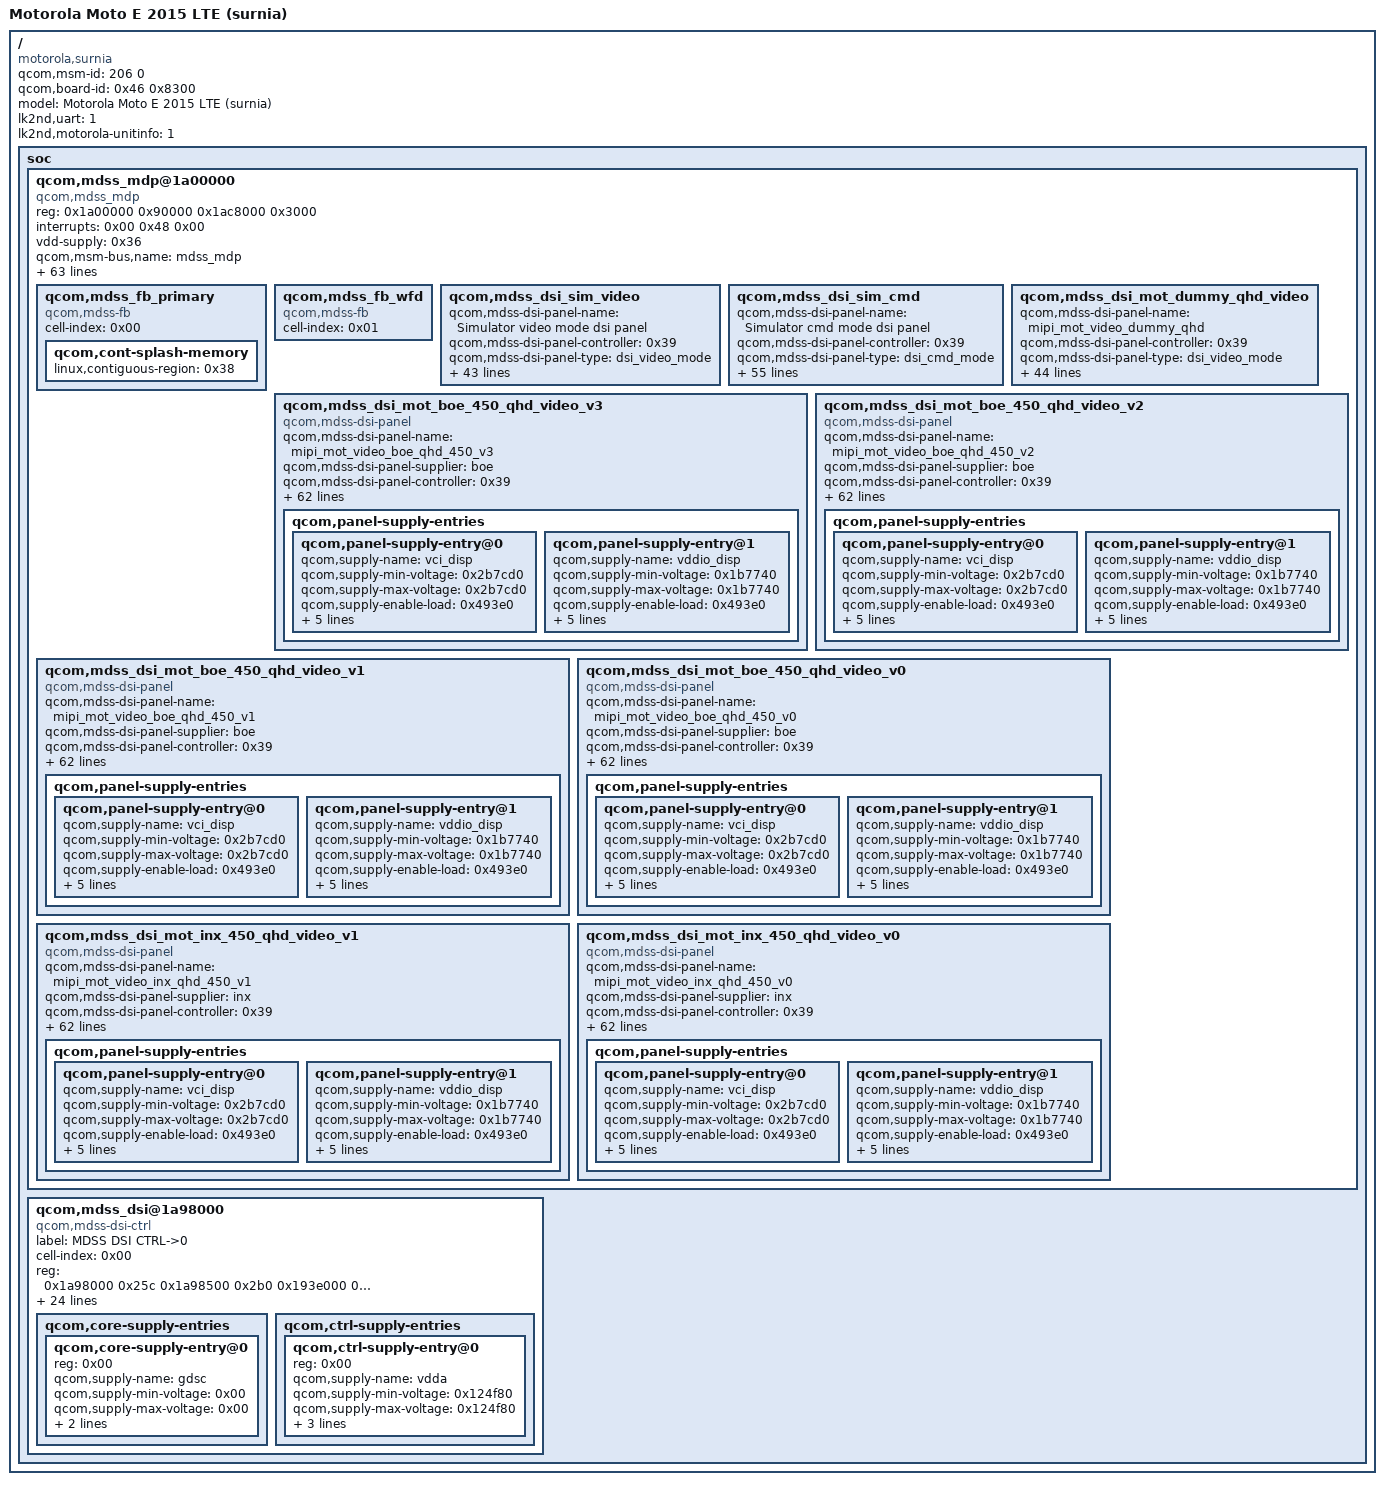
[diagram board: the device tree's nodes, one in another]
// SPDX-License-Identifier: GPL-2.0-only

/dts-v1/;

/include/ "msm8916.dtsi"
/include/ "motorola-carrier-channel-ids.dtsi"

/ {
	qcom,msm-id = <206 0>;
	qcom,board-id = <0x46 0x8300>;

	model = "Motorola Moto E 2015 LTE (surnia)";
	compatible = "motorola,surnia", "qcom,msm8916", "lk2nd,device";

	lk2nd,uart = <1>;
	lk2nd,motorola-unitinfo = <1>;

	soc {
		qcom,mdss_mdp@1a00000 {
			compatible = "qcom,mdss_mdp";
			reg = <0x1a00000 0x90000 0x1ac8000 0x3000>;
			reg-names = "mdp_phys\0vbif_phys";
			interrupts = <0x00 0x48 0x00>;
			vdd-supply = <0x36>;
			qcom,msm-bus,name = "mdss_mdp";
			qcom,msm-bus,num-cases = <0x03>;
			qcom,msm-bus,num-paths = <0x01>;
			qcom,msm-bus,vectors-KBps = <0x16 0x200 0x00 0x00 0x16 0x200 0x00 0x61a800 0x16 0x200 0x00 0x61a800>;
			qcom,mdss-ab-factor = <0x01 0x01>;
			qcom,mdss-ib-factor = <0x02 0x01>;
			qcom,mdss-clk-factor = <0x69 0x64>;
			qcom,max-bandwidth-low-kbps = <0x10c8e0>;
			qcom,max-bandwidth-high-kbps = <0x10c8e0>;
			qcom,mdss-vbif-qos-rt-setting = <0x02 0x02 0x02 0x02>;
			qcom,mdss-vbif-qos-nrt-setting = <0x01 0x01 0x01 0x01>;
			qcom,max-mixer-width = <0x800>;
			qcom,mdss-mdp-reg-offset = <0x1000>;
			qcom,max-clk-rate = <0x1312d000>;
			qcom,mdss-pipe-vig-off = <0x5000>;
			qcom,mdss-pipe-rgb-off = <0x15000 0x17000>;
			qcom,mdss-pipe-dma-off = <0x25000>;
			qcom,mdss-pipe-vig-fetch-id = <0x01>;
			qcom,mdss-pipe-rgb-fetch-id = <0x07 0x08>;
			qcom,mdss-pipe-dma-fetch-id = <0x04>;
			qcom,mdss-pipe-vig-xin-id = <0x00>;
			qcom,mdss-pipe-rgb-xin-id = <0x01 0x05>;
			qcom,mdss-pipe-dma-xin-id = <0x02>;
			qcom,mdss-pipe-vig-clk-ctrl-offsets = <0x2ac 0x00 0x00>;
			qcom,mdss-pipe-rgb-clk-ctrl-offsets = <0x2ac 0x04 0x08 0x2b4 0x04 0x08>;
			qcom,mdss-pipe-dma-clk-ctrl-offsets = <0x2ac 0x08 0x0c>;
			qcom,mdss-smp-data = <0x08 0x2000>;
			qcom,mdss-ctl-off = <0x2000 0x2200 0x2400>;
			qcom,mdss-mixer-intf-off = <0x45000>;
			qcom,mdss-mixer-wb-off = <0x48000>;
			qcom,mdss-dspp-off = <0x55000>;
			qcom,mdss-pingpong-off = <0x71000>;
			qcom,mdss-wb-off = <0x65000 0x65800 0x66000>;
			qcom,mdss-intf-off = <0x00 0x6b800>;
			qcom,mdss-rot-block-size = <0x40>;
			qcom,mdss-wfd-mode = "dedicated";
			qcom,mdss-has-non-scalar-rgb;
			qcom,mdss-has-decimation;
			qcom,mdss-traffic-shaper-enabled;
			qcom,mdss-no-hist-vote;
			vdd-cx-supply = <0x37>;
			clocks = <0x22 0xbfb92ed3 0x22 0x668f51de 0x22 0x6dc1f8f1 0x22 0x22f3521f 0x22 0x32a09f1f>;
			clock-names = "iface_clk\0bus_clk\0core_clk_src\0core_clk\0vsync_clk";
			qcom,mdp-settings = <0x11e4 0x00 0x65048 0x08 0x65848 0x08 0x66048 0x08>;
			qcom,mdss-prefill-outstanding-buffer-bytes = <0x400>;
			qcom,mdss-prefill-y-buffer-bytes = <0x00>;
			qcom,mdss-prefill-scaler-buffer-lines-bilinear = <0x02>;
			qcom,mdss-prefill-scaler-buffer-lines-caf = <0x04>;
			qcom,mdss-prefill-post-scaler-buffer-pixels = <0x00>;
			qcom,mdss-prefill-pingpong-buffer-pixels = <0x1000>;
			qcom,mdss-prefill-fbc-lines = <0x00>;
			qcom,mdss-pref-prim-intf = "dsi";
			linux,phandle = <0x3b>;
			phandle = <0x3b>;

			qcom,mdss_fb_primary {
				cell-index = <0x00>;
				compatible = "qcom,mdss-fb";
				linux,phandle = <0x3a>;
				phandle = <0x3a>;

				qcom,cont-splash-memory {
					linux,contiguous-region = <0x38>;
				};
			};

			qcom,mdss_fb_wfd {
				cell-index = <0x01>;
				compatible = "qcom,mdss-fb";
				linux,phandle = <0x43>;
				phandle = <0x43>;
			};

			qcom,mdss_dsi_sim_video {
				qcom,mdss-dsi-panel-name = "Simulator video mode dsi panel";
				qcom,mdss-dsi-panel-controller = <0x39>;
				qcom,mdss-dsi-panel-type = "dsi_video_mode";
				qcom,mdss-dsi-panel-destination = "display_1";
				qcom,mdss-dsi-panel-framerate = <0x3c>;
				qcom,mdss-dsi-virtual-channel-id = <0x00>;
				qcom,mdss-dsi-stream = <0x00>;
				qcom,mdss-dsi-panel-width = <0x280>;
				qcom,mdss-dsi-panel-height = <0x1e0>;
				qcom,mdss-dsi-h-front-porch = <0x06>;
				qcom,mdss-dsi-h-back-porch = <0x06>;
				qcom,mdss-dsi-h-pulse-width = <0x02>;
				qcom,mdss-dsi-h-sync-skew = <0x00>;
				qcom,mdss-dsi-v-back-porch = <0x06>;
				qcom,mdss-dsi-v-front-porch = <0x06>;
				qcom,mdss-dsi-v-pulse-width = <0x02>;
				qcom,mdss-dsi-h-left-border = <0x00>;
				qcom,mdss-dsi-h-right-border = <0x00>;
				qcom,mdss-dsi-v-top-border = <0x00>;
				qcom,mdss-dsi-v-bottom-border = <0x00>;
				qcom,mdss-dsi-bpp = <0x18>;
				qcom,mdss-dsi-underflow-color = <0xff>;
				qcom,mdss-dsi-border-color = <0x00>;
				qcom,mdss-dsi-on-command = [32 01 00 00 00 00 02 00 00];
				qcom,mdss-dsi-off-command = [22 01 00 00 00 00 02 00 00];
				qcom,mdss-dsi-on-command-state = "dsi_lp_mode";
				qcom,mdss-dsi-off-command-state = "dsi_lp_mode";
				qcom,mdss-dsi-h-sync-pulse = <0x00>;
				qcom,mdss-dsi-traffic-mode = "non_burst_sync_event";
				qcom,mdss-dsi-bllp-eof-power-mode;
				qcom,mdss-dsi-bllp-power-mode;
				qcom,mdss-dsi-lane-0-state;
				qcom,mdss-dsi-lane-1-state;
				qcom,mdss-dsi-lane-2-state;
				qcom,mdss-dsi-lane-3-state;
				qcom,mdss-dsi-panel-timings = <0x00 0x00 0x00>;
				qcom,mdss-dsi-t-clk-post = <0x04>;
				qcom,mdss-dsi-t-clk-pre = <0x1b>;
				qcom,mdss-dsi-dma-trigger = "trigger_sw";
				qcom,mdss-dsi-mdp-trigger = "none";
				qcom,mdss-dsi-reset-sequence = <0x01 0x00 0x00 0x00 0x01 0x00>;
				qcom,panel-ack-disabled;
			};

			qcom,mdss_dsi_sim_cmd {
				qcom,mdss-dsi-panel-name = "Simulator cmd mode dsi panel";
				qcom,mdss-dsi-panel-controller = <0x39>;
				qcom,mdss-dsi-panel-type = "dsi_cmd_mode";
				qcom,mdss-dsi-panel-destination = "display_1";
				qcom,mdss-dsi-panel-framerate = <0x3c>;
				qcom,mdss-dsi-virtual-channel-id = <0x00>;
				qcom,mdss-dsi-stream = <0x00>;
				qcom,mdss-dsi-panel-width = <0x438>;
				qcom,mdss-dsi-panel-height = <0x780>;
				qcom,mdss-dsi-h-front-porch = <0x60>;
				qcom,mdss-dsi-h-back-porch = <0x40>;
				qcom,mdss-dsi-h-pulse-width = <0x10>;
				qcom,mdss-dsi-h-sync-skew = <0x00>;
				qcom,mdss-dsi-v-back-porch = <0x10>;
				qcom,mdss-dsi-v-front-porch = <0x04>;
				qcom,mdss-dsi-v-pulse-width = <0x01>;
				qcom,mdss-dsi-h-left-border = <0x00>;
				qcom,mdss-dsi-h-right-border = <0x00>;
				qcom,mdss-dsi-v-top-border = <0x00>;
				qcom,mdss-dsi-v-bottom-border = <0x00>;
				qcom,mdss-dsi-bpp = <0x18>;
				qcom,mdss-dsi-color-order = "rgb_swap_rgb";
				qcom,mdss-dsi-underflow-color = <0xff>;
				qcom,mdss-dsi-border-color = <0x00>;
				qcom,mdss-dsi-h-sync-pulse = <0x00>;
				qcom,mdss-dsi-traffic-mode = "non_burst_sync_event";
				qcom,mdss-dsi-lane-map = "lane_map_0123";
				qcom,mdss-dsi-bllp-eof-power-mode;
				qcom,mdss-dsi-bllp-power-mode;
				qcom,mdss-dsi-lane-0-state;
				qcom,mdss-dsi-lane-1-state;
				qcom,mdss-dsi-lane-2-state;
				qcom,mdss-dsi-lane-3-state;
				qcom,mdss-dsi-hor-line-idle = <0x00 0x28 0x100 0x28 0x78 0x80 0x78 0xf0 0x40>;
				qcom,mdss-dsi-panel-timings = <0xcd322200 0x60642634 0x29030400>;
				qcom,mdss-dsi-reset-sequence = <0x01 0x0a 0x00 0x0a 0x01 0x0a>;
				qcom,mdss-dsi-t-clk-post = <0x03>;
				qcom,mdss-dsi-t-clk-pre = <0x27>;
				qcom,mdss-dsi-bl-max-level = <0xfff>;
				qcom,mdss-dsi-dma-trigger = "trigger_sw";
				qcom,mdss-dsi-mdp-trigger = "none";
				qcom,mdss-dsi-te-pin-select = <0x01>;
				qcom,mdss-dsi-wr-mem-start = <0x2c>;
				qcom,mdss-dsi-wr-mem-continue = <0x3c>;
				qcom,mdss-dsi-te-dcs-command = <0x01>;
				qcom,mdss-dsi-te-check-enable;
				qcom,mdss-dsi-te-using-te-pin;
				qcom,mdss-dsi-on-command = <0x29010000 0x2b0 0x3050100 0xa0001 0x150100 0xa0002 0x3a773901 0xa00 0x52a0000 0x4ff3901 0xa00 0x52b0000 0x59f1501 0xa00 0x2350039 0x100000a 0x34400 0x150100 0xa0002 0x51ff1501 0xa00 0x2532415 0x100000a 0x25500 0x5010000 0x78000111 0x5010000 0x10000129>;
				qcom,mdss-dsi-on-command-state = "dsi_lp_mode";
				qcom,mdss-dsi-off-command = [05 01 00 00 32 00 02 28 00 05 01 00 00 78 00 02 10 00];
				qcom,mdss-dsi-off-command-state = "dsi_hs_mode";
				qcom,panel-ack-disabled;
			};

			qcom,mdss_dsi_mot_dummy_qhd_video {
				qcom,mdss-dsi-panel-name = "mipi_mot_video_dummy_qhd";
				qcom,mdss-dsi-panel-controller = <0x39>;
				qcom,mdss-dsi-panel-type = "dsi_video_mode";
				qcom,mdss-dsi-panel-destination = "display_1";
				qcom,mdss-dsi-panel-framerate = <0x3c>;
				qcom,mdss-dsi-virtual-channel-id = <0x00>;
				qcom,mdss-dsi-stream = <0x00>;
				qcom,mdss-dsi-panel-width = <0x21c>;
				qcom,mdss-dsi-panel-height = <0x3c0>;
				qcom,mdss-pan-physical-width-dimension = <0x36>;
				qcom,mdss-pan-physical-height-dimension = <0x5f>;
				qcom,mdss-dsi-h-front-porch = <0x20>;
				qcom,mdss-dsi-h-back-porch = <0x04>;
				qcom,mdss-dsi-h-pulse-width = <0x20>;
				qcom,mdss-dsi-h-sync-skew = <0x00>;
				qcom,mdss-dsi-v-back-porch = <0x10>;
				qcom,mdss-dsi-v-front-porch = <0x0f>;
				qcom,mdss-dsi-v-pulse-width = <0x01>;
				qcom,mdss-dsi-h-left-border = <0x00>;
				qcom,mdss-dsi-h-right-border = <0x00>;
				qcom,mdss-dsi-v-top-border = <0x00>;
				qcom,mdss-dsi-v-bottom-border = <0x00>;
				qcom,mdss-dsi-bpp = <0x18>;
				qcom,mdss-dsi-underflow-color = <0xff>;
				qcom,mdss-dsi-border-color = <0x00>;
				qcom,mdss-dsi-on-command-state = "dsi_lp_mode";
				qcom,mdss-dsi-off-command-state = "dsi_lp_mode";
				qcom,mdss-dsi-h-sync-pulse = <0x00>;
				qcom,mdss-dsi-traffic-mode = "non_burst_sync_event";
				qcom,mdss-dsi-lane-map = "lane_map_3012";
				qcom,mdss-dsi-bllp-eof-power-mode;
				qcom,mdss-dsi-bllp-power-mode;
				qcom,mdss-dsi-lane-0-state;
				qcom,mdss-dsi-lane-1-state;
				qcom,mdss-dsi-tx-eot-append;
				qcom,mdss-dsi-panel-timings = <0x821c1200 0x4042161e 0x14030400>;
				qcom,mdss-dsi-t-clk-post = <0x04>;
				qcom,mdss-dsi-t-clk-pre = <0x1b>;
				qcom,mdss-dsi-bl-min-level = <0x01>;
				qcom,mdss-dsi-bl-max-level = <0xff>;
				qcom,mdss-dsi-dma-trigger = "trigger_sw";
				qcom,mdss-dsi-mdp-trigger = "none";
				qcom,mdss-dsi-bl-pmic-control-type = "bl_ctrl_dcs";
				qcom,mdss-dsi-reset-sequence = <0x01 0x00>;
			};

			qcom,mdss_dsi_mot_boe_450_qhd_video_v3 {
				compatible = "qcom,mdss-dsi-panel";
				qcom,mdss-dsi-panel-name = "mipi_mot_video_boe_qhd_450_v3";
				qcom,mdss-dsi-panel-supplier = "boe";
				qcom,mdss-dsi-panel-controller = <0x39>;
				qcom,mdss-dsi-panel-type = "dsi_video_mode";
				qcom,mdss-dsi-panel-destination = "display_1";
				qcom,mdss-dsi-panel-framerate = <0x3c>;
				qcom,mdss-dsi-virtual-channel-id = <0x00>;
				qcom,mdss-dsi-stream = <0x00>;
				qcom,mdss-dsi-panel-width = <0x21c>;
				qcom,mdss-dsi-panel-height = <0x3c0>;
				qcom,mdss-pan-physical-width-dimension = <0x37>;
				qcom,mdss-pan-physical-height-dimension = <0x63>;
				qcom,mdss-dsi-panel-clockrate = <0x00>;
				qcom,mdss-dsi-h-front-porch = <0x18>;
				qcom,mdss-dsi-h-back-porch = <0x28>;
				qcom,mdss-dsi-h-pulse-width = <0x04>;
				qcom,mdss-dsi-h-sync-skew = <0x00>;
				qcom,mdss-dsi-v-back-porch = <0x10>;
				qcom,mdss-dsi-v-front-porch = <0x10>;
				qcom,mdss-dsi-v-pulse-width = <0x02>;
				qcom,mdss-dsi-h-left-border = <0x00>;
				qcom,mdss-dsi-h-right-border = <0x00>;
				qcom,mdss-dsi-v-top-border = <0x00>;
				qcom,mdss-dsi-v-bottom-border = <0x00>;
				qcom,mdss-dsi-bpp = <0x18>;
				qcom,mdss-dsi-underflow-color = <0xff>;
				qcom,mdss-dsi-border-color = <0x00>;
				qcom,mdss-dsi-on-command = [15 01 00 00 00 00 02 53 2c 15 01 00 00 00 00 02 55 02 05 01 00 00 78 00 01 11 15 01 00 00 00 00 02 51 ff 05 01 00 00 28 00 01 29];
				qcom,mdss-dsi-off-command = <0x5010000 0xa000128 0x5010000 0x78000110>;
				qcom,mdss-dsi-on-command-state = "dsi_lp_mode";
				qcom,mdss-dsi-off-command-state = "dsi_lp_mode";
				qcom,mdss-dsi-h-sync-pulse = <0x00>;
				qcom,mdss-dsi-traffic-mode = "non_burst_sync_event";
				qcom,mdss-dsi-bllp-eof-power-mode;
				qcom,mdss-dsi-bllp-power-mode;
				qcom,mdss-dsi-lane-0-state;
				qcom,mdss-dsi-lane-1-state;
				qcom,mdss-dsi-panel-timings = <0x821c1200 0x4042161e 0x14030400>;
				qcom,mdss-dsi-t-clk-post = <0x04>;
				qcom,mdss-dsi-t-clk-pre = <0x1a>;
				qcom,mdss-dsi-bl-min-level = <0x01>;
				qcom,mdss-dsi-bl-max-level = <0xff>;
				qcom,mdss-dsi-bl-shutdown-delay = <0x28>;
				qcom,mdss-dsi-bl-on-defer-delay = <0x78>;
				qcom,mdss-dsi-dma-trigger = "trigger_sw";
				qcom,mdss-dsi-mdp-trigger = "none";
				qcom,mdss-dsi-bl-pmic-control-type = "bl_ctrl_wled";
				qcom,mdss-dsi-reset-sequence = <0x01 0x02 0x00 0x01 0x01 0x15>;
				qcom,mdss-dsi-lp11-init;
				qcom,mdss-dsi-tx-eot-append;
				qcom,esd-check-enabled;
				qcom,mdss-dsi-panel-status-check-mode = "reg_read";
				qcom,mdss-dsi-panel-status-command = <0x6010001 0x10a>;
				qcom,mdss-dsi-panel-status-command-state = "dsi_hs_mode";
				qcom,mdss-dsi-panel-status-value = <0x9c>;
				qcom,cont-splash-enabled;
				linux,phandle = <0x42>;
				phandle = <0x42>;

				qcom,panel-supply-entries {
					#address-cells = <0x01>;
					#size-cells = <0x00>;

					qcom,panel-supply-entry@0 {
						qcom,supply-name = "vci_disp";
						qcom,supply-min-voltage = <0x2b7cd0>;
						qcom,supply-max-voltage = <0x2b7cd0>;
						qcom,supply-enable-load = <0x493e0>;
						qcom,supply-disable-load = <0x64>;
						qcom,supply-pre-on-sleep = <0x00>;
						qcom,supply-post-on-sleep = <0x00>;
						qcom,supply-pre-off-sleep = <0x00>;
						qcom,supply-post-off-sleep = <0x00>;
					};

					qcom,panel-supply-entry@1 {
						qcom,supply-name = "vddio_disp";
						qcom,supply-min-voltage = <0x1b7740>;
						qcom,supply-max-voltage = <0x1b7740>;
						qcom,supply-enable-load = <0x493e0>;
						qcom,supply-disable-load = <0x64>;
						qcom,supply-pre-on-sleep = <0x00>;
						qcom,supply-post-on-sleep = <0x00>;
						qcom,supply-pre-off-sleep = <0x00>;
						qcom,supply-post-off-sleep = <0x00>;
					};
				};
			};

			qcom,mdss_dsi_mot_boe_450_qhd_video_v2 {
				compatible = "qcom,mdss-dsi-panel";
				qcom,mdss-dsi-panel-name = "mipi_mot_video_boe_qhd_450_v2";
				qcom,mdss-dsi-panel-supplier = "boe";
				qcom,mdss-dsi-panel-controller = <0x39>;
				qcom,mdss-dsi-panel-type = "dsi_video_mode";
				qcom,mdss-dsi-panel-destination = "display_1";
				qcom,mdss-dsi-panel-framerate = <0x3c>;
				qcom,mdss-dsi-virtual-channel-id = <0x00>;
				qcom,mdss-dsi-stream = <0x00>;
				qcom,mdss-dsi-panel-width = <0x21c>;
				qcom,mdss-dsi-panel-height = <0x3c0>;
				qcom,mdss-pan-physical-width-dimension = <0x37>;
				qcom,mdss-pan-physical-height-dimension = <0x63>;
				qcom,mdss-dsi-panel-clockrate = <0x00>;
				qcom,mdss-dsi-h-front-porch = <0x18>;
				qcom,mdss-dsi-h-back-porch = <0x28>;
				qcom,mdss-dsi-h-pulse-width = <0x04>;
				qcom,mdss-dsi-h-sync-skew = <0x00>;
				qcom,mdss-dsi-v-back-porch = <0x10>;
				qcom,mdss-dsi-v-front-porch = <0x10>;
				qcom,mdss-dsi-v-pulse-width = <0x02>;
				qcom,mdss-dsi-h-left-border = <0x00>;
				qcom,mdss-dsi-h-right-border = <0x00>;
				qcom,mdss-dsi-v-top-border = <0x00>;
				qcom,mdss-dsi-v-bottom-border = <0x00>;
				qcom,mdss-dsi-bpp = <0x18>;
				qcom,mdss-dsi-underflow-color = <0xff>;
				qcom,mdss-dsi-border-color = <0x00>;
				qcom,mdss-dsi-on-command = <0x29010000 0x6f0 0x55aa5208 0x290100 0x06 0xb0000c40 0x3c3c2901 0x00 0x3b16b06 0x13010000 0x2b6 0x9290100 0x03 0xb7030229 0x1000000 0x5b801 0x4040413 0x1000000 0x2ba01 0x29010000 0x3bb 0x63301301 0x00 0x2bc0029 0x1000000 0x4cc03 0x17502901 0x00 0xad40000 0x00 0x29 0x1000000 0x11d600 0x101 0x1010101 0x1010102 0x2020229 0x1000000 0xdd731 0x31313131 0x31313131 0x31313129 0x1000000 0xed831 0x31313131 0x31313131 0x31313131 0x29010000 0xbe3 0xf0e4ded7 0xd0cbc9c6 0xc3c02901 0x00 0x6f055aa 0x52080113 0x1000000 0x2b00a 0x13010000 0x2b6 0x33130100 0x02 0xb10a1301 0x00 0x2b72413 0x1000000 0x2b201 0x13010000 0x2b8 0x33130100 0x02 0xb30a1301 0x00 0x2b92313 0x1000000 0x2b40a 0x13010000 0x2ba 0x25150100 0x02 0x532c1501 0x00 0x2550205 0x1000078 0x11115 0x1000000 0x251ff 0x5010000 0x28000129>;
				qcom,mdss-dsi-off-command = <0x5010000 0xa000128 0x5010000 0x78000110>;
				qcom,mdss-dsi-on-command-state = "dsi_lp_mode";
				qcom,mdss-dsi-off-command-state = "dsi_lp_mode";
				qcom,mdss-dsi-h-sync-pulse = <0x00>;
				qcom,mdss-dsi-traffic-mode = "non_burst_sync_event";
				qcom,mdss-dsi-bllp-eof-power-mode;
				qcom,mdss-dsi-bllp-power-mode;
				qcom,mdss-dsi-lane-0-state;
				qcom,mdss-dsi-lane-1-state;
				qcom,mdss-dsi-panel-timings = <0x821c1200 0x4042161e 0x14030400>;
				qcom,mdss-dsi-t-clk-post = <0x04>;
				qcom,mdss-dsi-t-clk-pre = <0x1a>;
				qcom,mdss-dsi-bl-min-level = <0x01>;
				qcom,mdss-dsi-bl-max-level = <0xff>;
				qcom,mdss-dsi-bl-shutdown-delay = <0x28>;
				qcom,mdss-dsi-bl-on-defer-delay = <0x78>;
				qcom,mdss-dsi-dma-trigger = "trigger_sw";
				qcom,mdss-dsi-mdp-trigger = "none";
				qcom,mdss-dsi-bl-pmic-control-type = "bl_ctrl_wled";
				qcom,mdss-dsi-reset-sequence = <0x01 0x02 0x00 0x01 0x01 0x15>;
				qcom,mdss-dsi-lp11-init;
				qcom,mdss-dsi-tx-eot-append;
				qcom,esd-check-enabled;
				qcom,mdss-dsi-panel-status-check-mode = "reg_read";
				qcom,mdss-dsi-panel-status-command = <0x6010001 0x10a>;
				qcom,mdss-dsi-panel-status-command-state = "dsi_hs_mode";
				qcom,mdss-dsi-panel-status-value = <0x9c>;
				qcom,cont-splash-enabled;

				qcom,panel-supply-entries {
					#address-cells = <0x01>;
					#size-cells = <0x00>;

					qcom,panel-supply-entry@0 {
						qcom,supply-name = "vci_disp";
						qcom,supply-min-voltage = <0x2b7cd0>;
						qcom,supply-max-voltage = <0x2b7cd0>;
						qcom,supply-enable-load = <0x493e0>;
						qcom,supply-disable-load = <0x64>;
						qcom,supply-pre-on-sleep = <0x00>;
						qcom,supply-post-on-sleep = <0x00>;
						qcom,supply-pre-off-sleep = <0x00>;
						qcom,supply-post-off-sleep = <0x00>;
					};

					qcom,panel-supply-entry@1 {
						qcom,supply-name = "vddio_disp";
						qcom,supply-min-voltage = <0x1b7740>;
						qcom,supply-max-voltage = <0x1b7740>;
						qcom,supply-enable-load = <0x493e0>;
						qcom,supply-disable-load = <0x64>;
						qcom,supply-pre-on-sleep = <0x00>;
						qcom,supply-post-on-sleep = <0x00>;
						qcom,supply-pre-off-sleep = <0x00>;
						qcom,supply-post-off-sleep = <0x00>;
					};
				};
			};

			qcom,mdss_dsi_mot_boe_450_qhd_video_v1 {
				compatible = "qcom,mdss-dsi-panel";
				qcom,mdss-dsi-panel-name = "mipi_mot_video_boe_qhd_450_v1";
				qcom,mdss-dsi-panel-supplier = "boe";
				qcom,mdss-dsi-panel-controller = <0x39>;
				qcom,mdss-dsi-panel-type = "dsi_video_mode";
				qcom,mdss-dsi-panel-destination = "display_1";
				qcom,mdss-dsi-panel-framerate = <0x3c>;
				qcom,mdss-dsi-virtual-channel-id = <0x00>;
				qcom,mdss-dsi-stream = <0x00>;
				qcom,mdss-dsi-panel-width = <0x21c>;
				qcom,mdss-dsi-panel-height = <0x3c0>;
				qcom,mdss-pan-physical-width-dimension = <0x37>;
				qcom,mdss-pan-physical-height-dimension = <0x63>;
				qcom,mdss-dsi-panel-clockrate = <0x00>;
				qcom,mdss-dsi-h-front-porch = <0x18>;
				qcom,mdss-dsi-h-back-porch = <0x28>;
				qcom,mdss-dsi-h-pulse-width = <0x04>;
				qcom,mdss-dsi-h-sync-skew = <0x00>;
				qcom,mdss-dsi-v-back-porch = <0x10>;
				qcom,mdss-dsi-v-front-porch = <0x10>;
				qcom,mdss-dsi-v-pulse-width = <0x02>;
				qcom,mdss-dsi-h-left-border = <0x00>;
				qcom,mdss-dsi-h-right-border = <0x00>;
				qcom,mdss-dsi-v-top-border = <0x00>;
				qcom,mdss-dsi-v-bottom-border = <0x00>;
				qcom,mdss-dsi-bpp = <0x18>;
				qcom,mdss-dsi-underflow-color = <0xff>;
				qcom,mdss-dsi-border-color = <0x00>;
				qcom,mdss-dsi-on-command = [29 01 00 00 00 00 06 f0 55 aa 52 08 00 29 01 00 00 00 00 06 b0 00 0c 40 3c 3c 29 01 00 00 00 00 03 b1 fc 06 13 01 00 00 00 00 02 b6 09 29 01 00 00 00 00 03 b7 03 02 29 01 00 00 00 00 05 b8 01 02 02 02 13 01 00 00 00 00 02 ba 01 13 01 00 00 00 00 02 bc 00 29 01 00 00 00 00 04 cc 03 17 50 29 01 00 00 00 00 0a d4 00 00 00 00 00 00 00 00 00 29 01 00 00 00 00 11 d6 00 00 00 01 01 01 01 01 01 01 01 01 02 02 02 02 29 01 00 00 00 00 0d d7 31 31 31 31 31 31 31 31 31 31 31 31 29 01 00 00 00 00 0e d8 31 31 31 31 31 31 31 31 31 31 31 31 31 29 01 00 00 00 00 0b e3 f0 e4 de d7 d0 cb c9 c6 c3 c0 29 01 00 00 00 00 06 f0 55 aa 52 08 01 13 01 00 00 00 00 02 b0 0a 13 01 00 00 00 00 02 b6 43 13 01 00 00 00 00 02 b1 0a 13 01 00 00 00 00 02 b7 34 13 01 00 00 00 00 02 b2 00 13 01 00 00 00 00 02 b8 13 13 01 00 00 00 00 02 b3 0a 13 01 00 00 00 00 02 b9 23 13 01 00 00 00 00 02 b4 0a 13 01 00 00 00 00 02 ba 24 15 01 00 00 00 00 02 53 2c 15 01 00 00 00 00 02 55 02 05 01 00 00 78 00 01 11 15 01 00 00 00 00 02 51 ff 05 01 00 00 28 00 01 29];
				qcom,mdss-dsi-off-command = <0x5010000 0xa000128 0x5010000 0x78000110>;
				qcom,mdss-dsi-on-command-state = "dsi_lp_mode";
				qcom,mdss-dsi-off-command-state = "dsi_lp_mode";
				qcom,mdss-dsi-h-sync-pulse = <0x00>;
				qcom,mdss-dsi-traffic-mode = "non_burst_sync_event";
				qcom,mdss-dsi-bllp-eof-power-mode;
				qcom,mdss-dsi-bllp-power-mode;
				qcom,mdss-dsi-lane-0-state;
				qcom,mdss-dsi-lane-1-state;
				qcom,mdss-dsi-panel-timings = <0x821c1200 0x4042161e 0x14030400>;
				qcom,mdss-dsi-t-clk-post = <0x04>;
				qcom,mdss-dsi-t-clk-pre = <0x1a>;
				qcom,mdss-dsi-bl-min-level = <0x01>;
				qcom,mdss-dsi-bl-max-level = <0xff>;
				qcom,mdss-dsi-bl-shutdown-delay = <0x28>;
				qcom,mdss-dsi-bl-on-defer-delay = <0x78>;
				qcom,mdss-dsi-dma-trigger = "trigger_sw";
				qcom,mdss-dsi-mdp-trigger = "none";
				qcom,mdss-dsi-bl-pmic-control-type = "bl_ctrl_wled";
				qcom,mdss-dsi-reset-sequence = <0x01 0x02 0x00 0x01 0x01 0x15>;
				qcom,mdss-dsi-lp11-init;
				qcom,mdss-dsi-tx-eot-append;
				qcom,esd-check-enabled;
				qcom,mdss-dsi-panel-status-check-mode = "reg_read";
				qcom,mdss-dsi-panel-status-command = <0x6010001 0x10a>;
				qcom,mdss-dsi-panel-status-command-state = "dsi_hs_mode";
				qcom,mdss-dsi-panel-status-value = <0x9c>;
				qcom,cont-splash-enabled;

				qcom,panel-supply-entries {
					#address-cells = <0x01>;
					#size-cells = <0x00>;

					qcom,panel-supply-entry@0 {
						qcom,supply-name = "vci_disp";
						qcom,supply-min-voltage = <0x2b7cd0>;
						qcom,supply-max-voltage = <0x2b7cd0>;
						qcom,supply-enable-load = <0x493e0>;
						qcom,supply-disable-load = <0x64>;
						qcom,supply-pre-on-sleep = <0x00>;
						qcom,supply-post-on-sleep = <0x00>;
						qcom,supply-pre-off-sleep = <0x00>;
						qcom,supply-post-off-sleep = <0x00>;
					};

					qcom,panel-supply-entry@1 {
						qcom,supply-name = "vddio_disp";
						qcom,supply-min-voltage = <0x1b7740>;
						qcom,supply-max-voltage = <0x1b7740>;
						qcom,supply-enable-load = <0x493e0>;
						qcom,supply-disable-load = <0x64>;
						qcom,supply-pre-on-sleep = <0x00>;
						qcom,supply-post-on-sleep = <0x00>;
						qcom,supply-pre-off-sleep = <0x00>;
						qcom,supply-post-off-sleep = <0x00>;
					};
				};
			};

			qcom,mdss_dsi_mot_boe_450_qhd_video_v0 {
				compatible = "qcom,mdss-dsi-panel";
				qcom,mdss-dsi-panel-name = "mipi_mot_video_boe_qhd_450_v0";
				qcom,mdss-dsi-panel-supplier = "boe";
				qcom,mdss-dsi-panel-controller = <0x39>;
				qcom,mdss-dsi-panel-type = "dsi_video_mode";
				qcom,mdss-dsi-panel-destination = "display_1";
				qcom,mdss-dsi-panel-framerate = <0x3c>;
				qcom,mdss-dsi-virtual-channel-id = <0x00>;
				qcom,mdss-dsi-stream = <0x00>;
				qcom,mdss-dsi-panel-width = <0x21c>;
				qcom,mdss-dsi-panel-height = <0x3c0>;
				qcom,mdss-pan-physical-width-dimension = <0x37>;
				qcom,mdss-pan-physical-height-dimension = <0x63>;
				qcom,mdss-dsi-panel-clockrate = <0x00>;
				qcom,mdss-dsi-h-front-porch = <0x18>;
				qcom,mdss-dsi-h-back-porch = <0x28>;
				qcom,mdss-dsi-h-pulse-width = <0x04>;
				qcom,mdss-dsi-h-sync-skew = <0x00>;
				qcom,mdss-dsi-v-back-porch = <0x10>;
				qcom,mdss-dsi-v-front-porch = <0x10>;
				qcom,mdss-dsi-v-pulse-width = <0x02>;
				qcom,mdss-dsi-h-left-border = <0x00>;
				qcom,mdss-dsi-h-right-border = <0x00>;
				qcom,mdss-dsi-v-top-border = <0x00>;
				qcom,mdss-dsi-v-bottom-border = <0x00>;
				qcom,mdss-dsi-bpp = <0x18>;
				qcom,mdss-dsi-underflow-color = <0xff>;
				qcom,mdss-dsi-border-color = <0x00>;
				qcom,mdss-dsi-on-command = <0x29010000 0x6f0 0x55aa5208 0x290100 0x02 0xb6082901 0x00 0x3b70000 0x29010000 0x2bc 0x290100 0x04 0xcc030000 0x29010000 0x6f0 0x55aa5208 0x1290100 0x04 0xb00a0a0a 0x29010000 0x4b6 0x44444429 0x1000000 0x4b10a 0xa0a2901 0x00 0x4b72424 0x24290100 0x04 0xb2030303 0x29010000 0x4b8 0x33333329 0x1000000 0x4b30d 0xd0d2901 0x00 0x4b92424 0x24290100 0x04 0xb40a0a0a 0x29010000 0x4ba 0x24242429 0x1000000 0x4bc00 0x78002901 0x00 0x4bd0078 0x290100 0x02 0xbe4f2901 0x00 0x11d10095 0xa800b8 0xc900e2 0xf30102 0x12b2901 0x00 0x11d2015e 0x19501d1 0x2090234 0x2550268 0x29f2901 0x00 0x11d302d3 0x3020312 0x33f035e 0x384039b 0x3b92901 0x00 0x5d403f1 0x3ff2901 0x00 0x11d50043 0x580078 0x9000a2 0xc300de 0x10b2901 0x00 0x11d6012e 0x1650191 0x1d90214 0x2150248 0x27f2901 0x00 0x11d702a3 0x2d202f2 0x31f033e 0x364037b 0x3992901 0x00 0x5d803e1 0x3ff2901 0x00 0x11d90043 0x580078 0x9000a2 0xc300de 0x10b2901 0x00 0x11dd012e 0x1650191 0x1d90214 0x2150248 0x27f2901 0x00 0x11de02a3 0x2d202f2 0x31f033e 0x364037b 0x3992901 0x00 0x11e00095 0xa800b8 0xc900e2 0xf30102 0x12b2901 0x00 0x11e1015e 0x19501d1 0x2090234 0x2550268 0x29f2901 0x00 0x11e202d3 0x3020312 0x33f035e 0x384039b 0x3b92901 0x00 0x5e303f1 0x3ff2901 0x00 0x11e40043 0x580078 0x9000a2 0xc300de 0x10b2901 0x00 0x11e5012e 0x1650191 0x1d90214 0x2150248 0x27f2901 0x00 0x11e602a3 0x2d202f2 0x31f033e 0x364037b 0x3992901 0x00 0x5e703e1 0x3ff2901 0x00 0x11e80043 0x580078 0x9000a2 0xc300de 0x10b2901 0x00 0x11e9012e 0x1650191 0x1d90214 0x2150248 0x27f2901 0x00 0x11ea02a3 0x2d202f2 0x31f033e 0x364037b 0x3992901 0x00 0x5eb03e1 0x3ff0501 0x7800 0x1111501 0x00 0x2532c15 0x1000000 0x251ff 0x5010000 0x28000129>;
				qcom,mdss-dsi-off-command = <0x5010000 0xa000128 0x5010000 0x78000110>;
				qcom,mdss-dsi-on-command-state = "dsi_lp_mode";
				qcom,mdss-dsi-off-command-state = "dsi_lp_mode";
				qcom,mdss-dsi-h-sync-pulse = <0x00>;
				qcom,mdss-dsi-traffic-mode = "non_burst_sync_event";
				qcom,mdss-dsi-bllp-eof-power-mode;
				qcom,mdss-dsi-bllp-power-mode;
				qcom,mdss-dsi-lane-0-state;
				qcom,mdss-dsi-lane-1-state;
				qcom,mdss-dsi-panel-timings = <0x821c1200 0x4042161e 0x14030400>;
				qcom,mdss-dsi-t-clk-post = <0x04>;
				qcom,mdss-dsi-t-clk-pre = <0x1a>;
				qcom,mdss-dsi-bl-min-level = <0x01>;
				qcom,mdss-dsi-bl-max-level = <0xff>;
				qcom,mdss-dsi-bl-shutdown-delay = <0x28>;
				qcom,mdss-dsi-bl-on-defer-delay = <0x78>;
				qcom,mdss-dsi-dma-trigger = "trigger_sw";
				qcom,mdss-dsi-mdp-trigger = "none";
				qcom,mdss-dsi-bl-pmic-control-type = "bl_ctrl_wled";
				qcom,mdss-dsi-reset-sequence = <0x01 0x02 0x00 0x01 0x01 0x15>;
				qcom,mdss-dsi-lp11-init;
				qcom,mdss-dsi-tx-eot-append;
				qcom,esd-check-enabled;
				qcom,mdss-dsi-panel-status-check-mode = "reg_read";
				qcom,mdss-dsi-panel-status-command = <0x6010001 0x10a>;
				qcom,mdss-dsi-panel-status-command-state = "dsi_hs_mode";
				qcom,mdss-dsi-panel-status-value = <0x9c>;
				qcom,cont-splash-enabled;

				qcom,panel-supply-entries {
					#address-cells = <0x01>;
					#size-cells = <0x00>;

					qcom,panel-supply-entry@0 {
						qcom,supply-name = "vci_disp";
						qcom,supply-min-voltage = <0x2b7cd0>;
						qcom,supply-max-voltage = <0x2b7cd0>;
						qcom,supply-enable-load = <0x493e0>;
						qcom,supply-disable-load = <0x64>;
						qcom,supply-pre-on-sleep = <0x00>;
						qcom,supply-post-on-sleep = <0x00>;
						qcom,supply-pre-off-sleep = <0x00>;
						qcom,supply-post-off-sleep = <0x00>;
					};

					qcom,panel-supply-entry@1 {
						qcom,supply-name = "vddio_disp";
						qcom,supply-min-voltage = <0x1b7740>;
						qcom,supply-max-voltage = <0x1b7740>;
						qcom,supply-enable-load = <0x493e0>;
						qcom,supply-disable-load = <0x64>;
						qcom,supply-pre-on-sleep = <0x00>;
						qcom,supply-post-on-sleep = <0x00>;
						qcom,supply-pre-off-sleep = <0x00>;
						qcom,supply-post-off-sleep = <0x00>;
					};
				};
			};

			qcom,mdss_dsi_mot_inx_450_qhd_video_v1 {
				compatible = "qcom,mdss-dsi-panel";
				qcom,mdss-dsi-panel-name = "mipi_mot_video_inx_qhd_450_v1";
				qcom,mdss-dsi-panel-supplier = "inx";
				qcom,mdss-dsi-panel-controller = <0x39>;
				qcom,mdss-dsi-panel-type = "dsi_video_mode";
				qcom,mdss-dsi-panel-destination = "display_1";
				qcom,mdss-dsi-panel-framerate = <0x3c>;
				qcom,mdss-dsi-virtual-channel-id = <0x00>;
				qcom,mdss-dsi-stream = <0x00>;
				qcom,mdss-dsi-panel-width = <0x21c>;
				qcom,mdss-dsi-panel-height = <0x3c0>;
				qcom,mdss-pan-physical-width-dimension = <0x37>;
				qcom,mdss-pan-physical-height-dimension = <0x63>;
				qcom,mdss-dsi-panel-clockrate = <0x00>;
				qcom,mdss-dsi-h-front-porch = <0x18>;
				qcom,mdss-dsi-h-back-porch = <0x28>;
				qcom,mdss-dsi-h-pulse-width = <0x04>;
				qcom,mdss-dsi-h-sync-skew = <0x00>;
				qcom,mdss-dsi-v-back-porch = <0x13>;
				qcom,mdss-dsi-v-front-porch = <0x10>;
				qcom,mdss-dsi-v-pulse-width = <0x02>;
				qcom,mdss-dsi-h-left-border = <0x00>;
				qcom,mdss-dsi-h-right-border = <0x00>;
				qcom,mdss-dsi-v-top-border = <0x00>;
				qcom,mdss-dsi-v-bottom-border = <0x00>;
				qcom,mdss-dsi-bpp = <0x18>;
				qcom,mdss-dsi-underflow-color = <0xff>;
				qcom,mdss-dsi-border-color = <0x00>;
				qcom,mdss-dsi-on-command = [15 01 00 00 00 00 02 53 2c 15 01 00 00 00 00 02 55 02 05 01 00 00 78 00 01 11 15 01 00 00 00 00 02 51 ff 05 01 00 00 28 00 01 29];
				qcom,mdss-dsi-off-command = <0x5010000 0xa000128 0x5010000 0x78000110>;
				qcom,mdss-dsi-on-command-state = "dsi_lp_mode";
				qcom,mdss-dsi-off-command-state = "dsi_lp_mode";
				qcom,mdss-dsi-h-sync-pulse = <0x00>;
				qcom,mdss-dsi-traffic-mode = "non_burst_sync_event";
				qcom,mdss-dsi-bllp-eof-power-mode;
				qcom,mdss-dsi-bllp-power-mode;
				qcom,mdss-dsi-lane-0-state;
				qcom,mdss-dsi-lane-1-state;
				qcom,mdss-dsi-panel-timings = <0x821c1200 0x4042161e 0x14030400>;
				qcom,mdss-dsi-t-clk-post = <0x04>;
				qcom,mdss-dsi-t-clk-pre = <0x1b>;
				qcom,mdss-dsi-bl-min-level = <0x01>;
				qcom,mdss-dsi-bl-max-level = <0xff>;
				qcom,mdss-dsi-bl-shutdown-delay = <0x28>;
				qcom,mdss-dsi-bl-on-defer-delay = <0x78>;
				qcom,mdss-dsi-dma-trigger = "trigger_sw";
				qcom,mdss-dsi-mdp-trigger = "none";
				qcom,mdss-dsi-bl-pmic-control-type = "bl_ctrl_wled";
				qcom,mdss-dsi-reset-sequence = <0x01 0x02 0x00 0x01 0x01 0x15>;
				qcom,mdss-dsi-lp11-init;
				qcom,mdss-dsi-tx-eot-append;
				qcom,esd-check-enabled;
				qcom,mdss-dsi-panel-status-check-mode = "reg_read";
				qcom,mdss-dsi-panel-status-command = <0x6010001 0x10a>;
				qcom,mdss-dsi-panel-status-command-state = "dsi_hs_mode";
				qcom,mdss-dsi-panel-status-value = <0x9c>;
				qcom,cont-splash-enabled;

				qcom,panel-supply-entries {
					#address-cells = <0x01>;
					#size-cells = <0x00>;

					qcom,panel-supply-entry@0 {
						qcom,supply-name = "vci_disp";
						qcom,supply-min-voltage = <0x2b7cd0>;
						qcom,supply-max-voltage = <0x2b7cd0>;
						qcom,supply-enable-load = <0x493e0>;
						qcom,supply-disable-load = <0x64>;
						qcom,supply-pre-on-sleep = <0x00>;
						qcom,supply-post-on-sleep = <0x00>;
						qcom,supply-pre-off-sleep = <0x00>;
						qcom,supply-post-off-sleep = <0x00>;
					};

					qcom,panel-supply-entry@1 {
						qcom,supply-name = "vddio_disp";
						qcom,supply-min-voltage = <0x1b7740>;
						qcom,supply-max-voltage = <0x1b7740>;
						qcom,supply-enable-load = <0x493e0>;
						qcom,supply-disable-load = <0x64>;
						qcom,supply-pre-on-sleep = <0x00>;
						qcom,supply-post-on-sleep = <0x00>;
						qcom,supply-pre-off-sleep = <0x00>;
						qcom,supply-post-off-sleep = <0x00>;
					};
				};
			};

			qcom,mdss_dsi_mot_inx_450_qhd_video_v0 {
				compatible = "qcom,mdss-dsi-panel";
				qcom,mdss-dsi-panel-name = "mipi_mot_video_inx_qhd_450_v0";
				qcom,mdss-dsi-panel-supplier = "inx";
				qcom,mdss-dsi-panel-controller = <0x39>;
				qcom,mdss-dsi-panel-type = "dsi_video_mode";
				qcom,mdss-dsi-panel-destination = "display_1";
				qcom,mdss-dsi-panel-framerate = <0x3c>;
				qcom,mdss-dsi-virtual-channel-id = <0x00>;
				qcom,mdss-dsi-stream = <0x00>;
				qcom,mdss-dsi-panel-width = <0x21c>;
				qcom,mdss-dsi-panel-height = <0x3c0>;
				qcom,mdss-pan-physical-width-dimension = <0x37>;
				qcom,mdss-pan-physical-height-dimension = <0x63>;
				qcom,mdss-dsi-panel-clockrate = <0x00>;
				qcom,mdss-dsi-h-front-porch = <0x18>;
				qcom,mdss-dsi-h-back-porch = <0x28>;
				qcom,mdss-dsi-h-pulse-width = <0x04>;
				qcom,mdss-dsi-h-sync-skew = <0x00>;
				qcom,mdss-dsi-v-back-porch = <0x13>;
				qcom,mdss-dsi-v-front-porch = <0x10>;
				qcom,mdss-dsi-v-pulse-width = <0x02>;
				qcom,mdss-dsi-h-left-border = <0x00>;
				qcom,mdss-dsi-h-right-border = <0x00>;
				qcom,mdss-dsi-v-top-border = <0x00>;
				qcom,mdss-dsi-v-bottom-border = <0x00>;
				qcom,mdss-dsi-bpp = <0x18>;
				qcom,mdss-dsi-underflow-color = <0xff>;
				qcom,mdss-dsi-border-color = <0x00>;
				qcom,mdss-dsi-on-command = [29 01 00 00 00 00 05 ff aa 55 25 81 29 01 00 00 00 00 2b f9 02 a0 00 00 15 15 04 0b 08 0a 09 10 12 05 00 15 0c 15 15 15 15 15 15 15 15 15 15 15 15 06 15 12 0d 00 02 09 08 0a 07 0e 15 15 29 01 00 00 00 00 05 f9 00 1a 00 40 29 01 00 00 00 00 06 f0 55 aa 52 08 00 13 01 00 00 00 00 02 b4 78 13 01 00 00 00 00 02 b6 09 29 01 00 00 00 00 03 b7 70 70 29 01 00 00 00 00 05 b8 01 04 04 04 13 01 00 00 00 00 02 bc 00 29 01 00 00 00 00 03 b1 68 06 13 01 00 00 00 00 02 c1 01 29 01 00 00 00 00 0c ca 01 e4 e4 e4 00 00 00 02 02 00 00 29 01 00 00 00 00 0a d4 00 00 00 00 00 00 00 00 00 29 01 00 00 00 00 11 d6 00 00 00 01 01 01 01 01 01 01 01 01 02 02 02 02 29 01 00 00 00 00 0d d7 31 31 31 31 31 31 31 31 31 31 31 31 29 01 00 00 00 00 0e d8 31 31 31 31 31 31 31 31 31 31 31 31 31 29 01 00 00 00 00 0b e3 f0 e4 de d7 d0 cb c9 c6 c3 c0 29 01 00 00 00 00 06 f0 55 aa 52 08 01 13 01 00 00 00 00 02 b0 0a 13 01 00 00 00 00 02 b1 0a 13 01 00 00 00 00 02 b2 00 13 01 00 00 00 00 02 b3 10 13 01 00 00 00 00 02 b4 06 13 01 00 00 00 00 02 b6 44 13 01 00 00 00 00 02 b7 34 13 01 00 00 00 00 02 b8 14 13 01 00 00 00 00 02 b9 35 13 01 00 00 00 00 02 ba 14 13 01 00 00 00 00 02 c2 00 13 01 00 00 00 00 02 cf 00 29 01 00 00 00 00 06 f0 55 aa 52 00 00 15 01 00 00 00 00 02 53 2c 15 01 00 00 00 00 02 55 02 05 01 00 00 78 00 01 11 15 01 00 00 00 00 02 51 ff 05 01 00 00 28 00 01 29];
				qcom,mdss-dsi-off-command = <0x5010000 0xa000128 0x5010000 0x78000110>;
				qcom,mdss-dsi-on-command-state = "dsi_lp_mode";
				qcom,mdss-dsi-off-command-state = "dsi_lp_mode";
				qcom,mdss-dsi-h-sync-pulse = <0x00>;
				qcom,mdss-dsi-traffic-mode = "non_burst_sync_event";
				qcom,mdss-dsi-bllp-eof-power-mode;
				qcom,mdss-dsi-bllp-power-mode;
				qcom,mdss-dsi-lane-0-state;
				qcom,mdss-dsi-lane-1-state;
				qcom,mdss-dsi-panel-timings = <0x821c1200 0x4042161e 0x14030400>;
				qcom,mdss-dsi-t-clk-post = <0x04>;
				qcom,mdss-dsi-t-clk-pre = <0x1b>;
				qcom,mdss-dsi-bl-min-level = <0x01>;
				qcom,mdss-dsi-bl-max-level = <0xff>;
				qcom,mdss-dsi-bl-shutdown-delay = <0x28>;
				qcom,mdss-dsi-bl-on-defer-delay = <0x78>;
				qcom,mdss-dsi-dma-trigger = "trigger_sw";
				qcom,mdss-dsi-mdp-trigger = "none";
				qcom,mdss-dsi-bl-pmic-control-type = "bl_ctrl_wled";
				qcom,mdss-dsi-reset-sequence = <0x01 0x02 0x00 0x01 0x01 0x15>;
				qcom,mdss-dsi-lp11-init;
				qcom,mdss-dsi-tx-eot-append;
				qcom,esd-check-enabled;
				qcom,mdss-dsi-panel-status-check-mode = "reg_read";
				qcom,mdss-dsi-panel-status-command = <0x6010001 0x10a>;
				qcom,mdss-dsi-panel-status-command-state = "dsi_hs_mode";
				qcom,mdss-dsi-panel-status-value = <0x9c>;
				qcom,cont-splash-enabled;

				qcom,panel-supply-entries {
					#address-cells = <0x01>;
					#size-cells = <0x00>;

					qcom,panel-supply-entry@0 {
						qcom,supply-name = "vci_disp";
						qcom,supply-min-voltage = <0x2b7cd0>;
						qcom,supply-max-voltage = <0x2b7cd0>;
						qcom,supply-enable-load = <0x493e0>;
						qcom,supply-disable-load = <0x64>;
						qcom,supply-pre-on-sleep = <0x00>;
						qcom,supply-post-on-sleep = <0x00>;
						qcom,supply-pre-off-sleep = <0x00>;
						qcom,supply-post-off-sleep = <0x00>;
					};

					qcom,panel-supply-entry@1 {
						qcom,supply-name = "vddio_disp";
						qcom,supply-min-voltage = <0x1b7740>;
						qcom,supply-max-voltage = <0x1b7740>;
						qcom,supply-enable-load = <0x493e0>;
						qcom,supply-disable-load = <0x64>;
						qcom,supply-pre-on-sleep = <0x00>;
						qcom,supply-post-on-sleep = <0x00>;
						qcom,supply-pre-off-sleep = <0x00>;
						qcom,supply-post-off-sleep = <0x00>;
					};
				};
			};
		};

		qcom,mdss_dsi@1a98000 {
			compatible = "qcom,mdss-dsi-ctrl";
			label = "MDSS DSI CTRL->0";
			cell-index = <0x00>;
			reg = <0x1a98000 0x25c 0x1a98500 0x2b0 0x193e000 0x30>;
			reg-names = "dsi_ctrl\0dsi_phy\0mmss_misc_phys";
			qcom,mdss-fb-map = <0x3a>;
			qcom,mdss-mdp = <0x3b>;
			gdsc-supply = <0x36>;
			vdda-supply = <0x23>;
			vdd-supply = <0x2b>;
			vddio-supply = <0x3c>;
			clocks = <0x22 0x22f3521f 0x22 0xbfb92ed3 0x22 0x668f51de 0x3d 0x35da7862 0x3d 0xcc5c5c77 0x22 0xaec5cb25>;
			clock-names = "mdp_core_clk\0iface_clk\0bus_clk\0byte_clk\0pixel_clk\0core_clk";
			qcom,platform-strength-ctrl = [ff 06];
			qcom,platform-bist-ctrl = [00 00 b1 ff 00 00];
			qcom,platform-regulator-settings = [02 09 03 00 20 00 01];
			qcom,platform-lane-config = [00 00 00 00 00 00 00 01 97 00 00 00 00 05 00 00 01 97 00 00 00 00 0a 00 00 01 97 00 00 00 00 0f 00 00 01 97 00 c0 00 00 00 00 00 01 bb];
			qcom,mmss-ulp-clamp-ctrl-offset = <0x20>;
			qcom,mmss-phyreset-ctrl-offset = <0x24>;
			qcom,timing-db-mode;
			pinctrl-names = "mdss_default\0mdss_sleep";
			pinctrl-0 = <0x3e 0x3f>;
			pinctrl-1 = <0x40 0x41>;
			qcom,platform-reset-gpio = <0x28 0x4e 0x00>;
			qcom,regulator-ldo-mode;
			qcom,dsi-pref-prim-pan = <0x42>;
			vci_disp-supply = <0x2b>;
			vddio_disp-supply = <0x3c>;
			linux,phandle = <0x39>;
			phandle = <0x39>;

			qcom,core-supply-entries {
				#address-cells = <0x01>;
				#size-cells = <0x00>;

				qcom,core-supply-entry@0 {
					reg = <0x00>;
					qcom,supply-name = "gdsc";
					qcom,supply-min-voltage = <0x00>;
					qcom,supply-max-voltage = <0x00>;
					qcom,supply-enable-load = <0x00>;
					qcom,supply-disable-load = <0x00>;
				};
			};

			qcom,ctrl-supply-entries {
				#address-cells = <0x01>;
				#size-cells = <0x00>;

				qcom,ctrl-supply-entry@0 {
					reg = <0x00>;
					qcom,supply-name = "vdda";
					qcom,supply-min-voltage = <0x124f80>;
					qcom,supply-max-voltage = <0x124f80>;
					qcom,supply-enable-load = <0x186a0>;
					qcom,supply-disable-load = <0x64>;
					qcom,supply-post-on-sleep = <0x14>;
				};
			};
		};
	};
};
